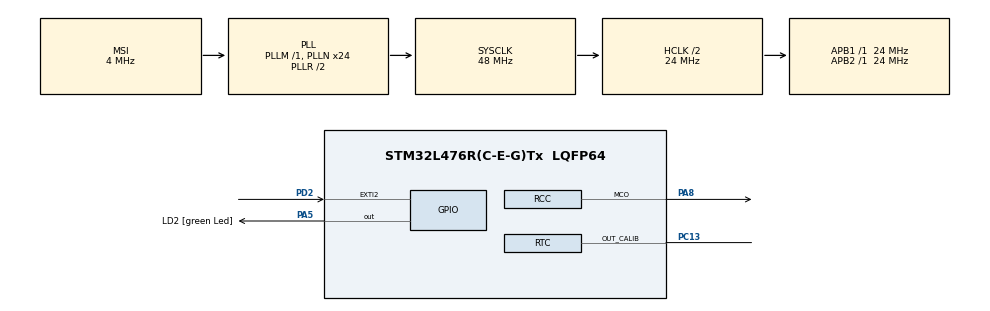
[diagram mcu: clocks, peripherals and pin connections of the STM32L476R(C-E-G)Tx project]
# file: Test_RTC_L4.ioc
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Mcu.Family=STM32L4
Mcu.Name=STM32L476R(C-E-G)Tx
Mcu.Package=LQFP64
NVIC.EXTI2_IRQn=true\:0\:0\:false\:false\:true\:true\:true
NVIC.PriorityGroup=NVIC_PRIORITYGROUP_4
PA13\ (JTMS-SWDIO).GPIO_Label=TMS
PA13\ (JTMS-SWDIO).Mode=Serial_Wire
PA13\ (JTMS-SWDIO).Signal=SYS_JTMS-SWDIO
PA14\ (JTCK-SWCLK).GPIO_Label=TCK
PA14\ (JTCK-SWCLK).Mode=Serial_Wire
PA14\ (JTCK-SWCLK).Signal=SYS_JTCK-SWCLK
PA2.Mode=Clock-out-LSCO
PA2.Signal=RCC_LSCO
PA5.GPIO_Label=LD2 [green Led]
PA5.GPIO_ModeDefaultOutputPP=GPIO_MODE_OUTPUT_PP
PA5.GPIO_PuPd=GPIO_NOPULL
PA5.GPIO_Speed=GPIO_SPEED_FREQ_LOW
PA5.Signal=GPIO_Output
PA8.GPIO_Speed=GPIO_SPEED_FREQ_VERY_HIGH
PA8.Mode=Clock-out
PA8.Signal=RCC_MCO
PB3\ (JTDO-TRACESWO).GPIO_Label=SWO
PB3\ (JTDO-TRACESWO).Signal=SYS_JTDO-SWO
PC13.Mode=Calibration_1Hz
PC13.Signal=RTC_OUT_CALIB
PC14-OSC32_IN\ (PC14).Mode=LSE-External-Oscillator
PC14-OSC32_IN\ (PC14).Signal=RCC_OSC32_IN
PC15-OSC32_OUT\ (PC15).Mode=LSE-External-Oscillator
PC15-OSC32_OUT\ (PC15).Signal=RCC_OSC32_OUT
PD2.Signal=GPXTI2
PH0-OSC_IN\ (PH0).Mode=HSE-External-Oscillator
PH0-OSC_IN\ (PH0).Signal=RCC_OSC_IN
PH1-OSC_OUT\ (PH1).Mode=HSE-External-Oscillator
PH1-OSC_OUT\ (PH1).Signal=RCC_OSC_OUT
ProjectManager.HeapSize=0x200
ProjectManager.StackSize=0x400
ProjectManager.TargetToolchain=TrueSTUDIO
RCC.ADCFreq_Value=16000000
RCC.AHBCLKDivider=RCC_SYSCLK_DIV2
RCC.AHBFreq_Value=24000000
RCC.APB1Freq_Value=24000000
RCC.APB1TimFreq_Value=24000000
RCC.APB2Freq_Value=24000000
RCC.APB2TimFreq_Value=24000000
RCC.CortexFreq_Value=24000000
RCC.HCLKFreq_Value=24000000
RCC.HSE_VALUE=8000000
RCC.HSI_VALUE=16000000
RCC.LPTIM1CLockSelection=RCC_LPTIM1CLKSOURCE_LSE
RCC.LSCOSource1=RCC_LSCOSOURCE_LSE
RCC.MSI_VALUE=4000000
RCC.PLLN=24
RCC.PREFETCH_ENABLE=1
RCC.RTCClockSelection=RCC_RTCCLKSOURCE_LSE
RCC.SYSCLKFreq_VALUE=48000000
RCC.SYSCLKSource=RCC_SYSCLKSOURCE_PLLCLK
RCC.USBFreq_Value=16000000
RCC.VCOOutputFreq_Value=96000000
VP_RTC_VS_RTC_Activate.Mode=RTC_Enabled
board=NUCLEO-L476RG

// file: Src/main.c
/* USER CODE BEGIN Header */
/**
  ******************************************************************************
  * @file           : main.c
  * @brief          : Main program body
  ******************************************************************************
  * @attention
  *
  * <h2><center>&copy; Copyright (c) 2020 STMicroelectronics.
  * All rights reserved.</center></h2>
  *
  * This software component is licensed by ST under BSD 3-Clause license,
  * the "License"; You may not use this file except in compliance with the
  * License. You may obtain a copy of the License at:
  *                        opensource.org/licenses/BSD-3-Clause
  *
  ******************************************************************************
  */
/* USER CODE END Header */

#include "main.h"

RTC_HandleTypeDef hrtc;

void SystemClock_Config(void);
static void MX_GPIO_Init(void);
static void MX_RTC_Init(void);

int main(void)
{

  /* MCU Configuration--------------------------------------------------------*/

  /* Reset of all peripherals, Initializes the Flash interface and the Systick. */
  HAL_Init();

  /* Configure the system clock */
  SystemClock_Config();

  /* Initialize all configured peripherals */
  MX_GPIO_Init();
  MX_RTC_Init();

  /* Infinite loop */
  while (1)
  {

    /* USER CODE BEGIN 3 */
	  __NOP();
  }
  /* USER CODE END 3 */
}

void SystemClock_Config(void)
{
  RCC_OscInitTypeDef RCC_OscInitStruct = {0};
  RCC_ClkInitTypeDef RCC_ClkInitStruct = {0};
  RCC_PeriphCLKInitTypeDef PeriphClkInit = {0};

  /** Configure LSE Drive Capability
  */
  HAL_PWR_EnableBkUpAccess();
  __HAL_RCC_LSEDRIVE_CONFIG(RCC_LSEDRIVE_LOW);
  /** Initializes the CPU, AHB and APB busses clocks
  */
  RCC_OscInitStruct.OscillatorType = RCC_OSCILLATORTYPE_LSE|RCC_OSCILLATORTYPE_MSI;
  RCC_OscInitStruct.LSEState = RCC_LSE_ON;
  RCC_OscInitStruct.MSIState = RCC_MSI_ON;
  RCC_OscInitStruct.MSICalibrationValue = 0;
  RCC_OscInitStruct.MSIClockRange = RCC_MSIRANGE_6;
  RCC_OscInitStruct.PLL.PLLState = RCC_PLL_ON;
  RCC_OscInitStruct.PLL.PLLSource = RCC_PLLSOURCE_MSI;
  RCC_OscInitStruct.PLL.PLLM = 1;
  RCC_OscInitStruct.PLL.PLLN = 24;
  RCC_OscInitStruct.PLL.PLLP = RCC_PLLP_DIV7;
  RCC_OscInitStruct.PLL.PLLQ = RCC_PLLQ_DIV2;
  RCC_OscInitStruct.PLL.PLLR = RCC_PLLR_DIV2;
  if (HAL_RCC_OscConfig(&RCC_OscInitStruct) != HAL_OK)
  {
    Error_Handler();
  }
  /** Initializes the CPU, AHB and APB busses clocks
  */
  RCC_ClkInitStruct.ClockType = RCC_CLOCKTYPE_HCLK|RCC_CLOCKTYPE_SYSCLK
                              |RCC_CLOCKTYPE_PCLK1|RCC_CLOCKTYPE_PCLK2;
  RCC_ClkInitStruct.SYSCLKSource = RCC_SYSCLKSOURCE_PLLCLK;
  RCC_ClkInitStruct.AHBCLKDivider = RCC_SYSCLK_DIV2;
  RCC_ClkInitStruct.APB1CLKDivider = RCC_HCLK_DIV1;
  RCC_ClkInitStruct.APB2CLKDivider = RCC_HCLK_DIV1;

  if (HAL_RCC_ClockConfig(&RCC_ClkInitStruct, FLASH_LATENCY_1) != HAL_OK)
  {
    Error_Handler();
  }
  PeriphClkInit.PeriphClockSelection = RCC_PERIPHCLK_RTC;
  PeriphClkInit.RTCClockSelection = RCC_RTCCLKSOURCE_LSE;
  if (HAL_RCCEx_PeriphCLKConfig(&PeriphClkInit) != HAL_OK)
  {
    Error_Handler();
  }
  HAL_RCC_MCOConfig(RCC_MCO1, RCC_MCO1SOURCE_SYSCLK, RCC_MCODIV_1);
  HAL_RCCEx_EnableLSCO(RCC_LSCOSOURCE_LSE);
  /** Configure the main internal regulator output voltage
  */
  if (HAL_PWREx_ControlVoltageScaling(PWR_REGULATOR_VOLTAGE_SCALE1) != HAL_OK)
  {
    Error_Handler();
  }
  /** Enable MSI Auto calibration
  */
  HAL_RCCEx_EnableMSIPLLMode();
}

static void MX_RTC_Init(void)
{

  /** Initialize RTC Only
  */
  hrtc.Instance = RTC;
  hrtc.Init.HourFormat = RTC_HOURFORMAT_24;
  hrtc.Init.AsynchPrediv = 127;
  hrtc.Init.SynchPrediv = 255;
  hrtc.Init.OutPut = RTC_OUTPUT_DISABLE;
  hrtc.Init.OutPutRemap = RTC_OUTPUT_REMAP_NONE;
  hrtc.Init.OutPutPolarity = RTC_OUTPUT_POLARITY_HIGH;
  hrtc.Init.OutPutType = RTC_OUTPUT_TYPE_OPENDRAIN;
  if (HAL_RTC_Init(&hrtc) != HAL_OK)
  {
    Error_Handler();
  }
  /** Enable Calibration
  */
  if (HAL_RTCEx_SetCalibrationOutPut(&hrtc, RTC_CALIBOUTPUT_1HZ) != HAL_OK)
  {
    Error_Handler();
  }

}

static void MX_GPIO_Init(void)
{
  GPIO_InitTypeDef GPIO_InitStruct = {0};

  /* GPIO Ports Clock Enable */
  __HAL_RCC_GPIOC_CLK_ENABLE();
  __HAL_RCC_GPIOH_CLK_ENABLE();
  __HAL_RCC_GPIOA_CLK_ENABLE();
  __HAL_RCC_GPIOD_CLK_ENABLE();
  __HAL_RCC_GPIOB_CLK_ENABLE();

  /*Configure GPIO pin Output Level */
  HAL_GPIO_WritePin(LD2_GPIO_Port, LD2_Pin, GPIO_PIN_RESET);

  /*Configure GPIO pin : PA2 */
  GPIO_InitStruct.Pin = GPIO_PIN_2;
  GPIO_InitStruct.Mode = GPIO_MODE_ANALOG;
  GPIO_InitStruct.Pull = GPIO_NOPULL;
  HAL_GPIO_Init(GPIOA, &GPIO_InitStruct);

  /*Configure GPIO pin : LD2_Pin */
  GPIO_InitStruct.Pin = LD2_Pin;
  GPIO_InitStruct.Mode = GPIO_MODE_OUTPUT_PP;
  GPIO_InitStruct.Pull = GPIO_NOPULL;
  GPIO_InitStruct.Speed = GPIO_SPEED_FREQ_LOW;
  HAL_GPIO_Init(LD2_GPIO_Port, &GPIO_InitStruct);

  /*Configure GPIO pin : PA8 */
  GPIO_InitStruct.Pin = GPIO_PIN_8;
  GPIO_InitStruct.Mode = GPIO_MODE_AF_PP;
  GPIO_InitStruct.Pull = GPIO_NOPULL;
  GPIO_InitStruct.Speed = GPIO_SPEED_FREQ_VERY_HIGH;
  GPIO_InitStruct.Alternate = GPIO_AF0_MCO;
  HAL_GPIO_Init(GPIOA, &GPIO_InitStruct);

  /*Configure GPIO pin : PD2 */
  GPIO_InitStruct.Pin = GPIO_PIN_2;
  GPIO_InitStruct.Mode = GPIO_MODE_IT_RISING;
  GPIO_InitStruct.Pull = GPIO_NOPULL;
  HAL_GPIO_Init(GPIOD, &GPIO_InitStruct);

  /* EXTI interrupt init*/
  HAL_NVIC_SetPriority(EXTI2_IRQn, 0, 0);
  HAL_NVIC_EnableIRQ(EXTI2_IRQn);

}

void Error_Handler(void)
{
}

/************************ (C) COPYRIGHT STMicroelectronics *****END OF FILE****/
